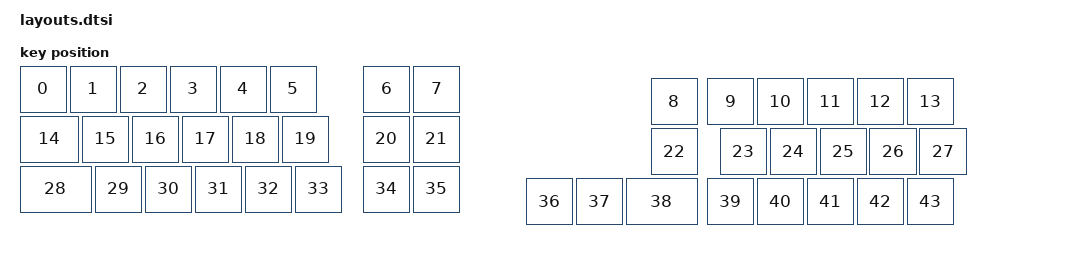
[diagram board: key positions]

#include <physical_layouts.dtsi>
/ {
    physical_layout0: physical_layout0 {
        compatible = "zmk,physical-layout";
        display-name = "Layout";
        keys
            = <&key_physical_attrs 100 100 (-37) 0 0 0 0>
			,<&key_physical_attrs 100 100 63 0 0 0 0>
			,<&key_physical_attrs 100 100 163 0 0 0 0>
			,<&key_physical_attrs 100 100 263 0 0 0 0>
			,<&key_physical_attrs 100 100 363 0 0 0 0>
			,<&key_physical_attrs 100 100 463 0 0 0 0>
			,<&key_physical_attrs 100 100 650 0 0 0 0>
			,<&key_physical_attrs 100 100 750 0 0 0 0>
			,<&key_physical_attrs 100 100 1225 25 0 0 0>
			,<&key_physical_attrs 100 100 1338 25 0 0 0>
			,<&key_physical_attrs 100 100 1438 25 0 0 0>
			,<&key_physical_attrs 100 100 1538 25 0 0 0>
			,<&key_physical_attrs 100 100 1638 25 0 0 0>
			,<&key_physical_attrs 100 100 1738 25 0 0 0>
			,<&key_physical_attrs 125 100 (-37) 100 0 0 0>
			,<&key_physical_attrs 100 100 88 100 0 0 0>
			,<&key_physical_attrs 100 100 188 100 0 0 0>
			,<&key_physical_attrs 100 100 288 100 0 0 0>
			,<&key_physical_attrs 100 100 388 100 0 0 0>
			,<&key_physical_attrs 100 100 488 100 0 0 0>
			,<&key_physical_attrs 100 100 650 100 0 0 0>
			,<&key_physical_attrs 100 100 750 100 0 0 0>
			,<&key_physical_attrs 100 100 1225 125 0 0 0>
			,<&key_physical_attrs 100 100 1363 125 0 0 0>
			,<&key_physical_attrs 100 100 1463 125 0 0 0>
			,<&key_physical_attrs 100 100 1563 125 0 0 0>
			,<&key_physical_attrs 100 100 1663 125 0 0 0>
			,<&key_physical_attrs 100 100 1763 125 0 0 0>
			,<&key_physical_attrs 150 100 (-37) 200 0 0 0>
			,<&key_physical_attrs 100 100 113 200 0 0 0>
			,<&key_physical_attrs 100 100 213 200 0 0 0>
			,<&key_physical_attrs 100 100 313 200 0 0 0>
			,<&key_physical_attrs 100 100 413 200 0 0 0>
			,<&key_physical_attrs 100 100 513 200 0 0 0>
			,<&key_physical_attrs 100 100 650 200 0 0 0>
			,<&key_physical_attrs 100 100 750 200 0 0 0>
			,<&key_physical_attrs 100 100 975 225 0 0 0>
			,<&key_physical_attrs 100 100 1075 225 0 0 0>
			,<&key_physical_attrs 150 100 1175 225 0 0 0>
			,<&key_physical_attrs 100 100 1338 225 0 0 0>
			,<&key_physical_attrs 100 100 1438 225 0 0 0>
			,<&key_physical_attrs 100 100 1538 225 0 0 0>
			,<&key_physical_attrs 100 100 1638 225 0 0 0>
			,<&key_physical_attrs 100 100 1738 225 0 0 0>
            ;
    };
};
    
